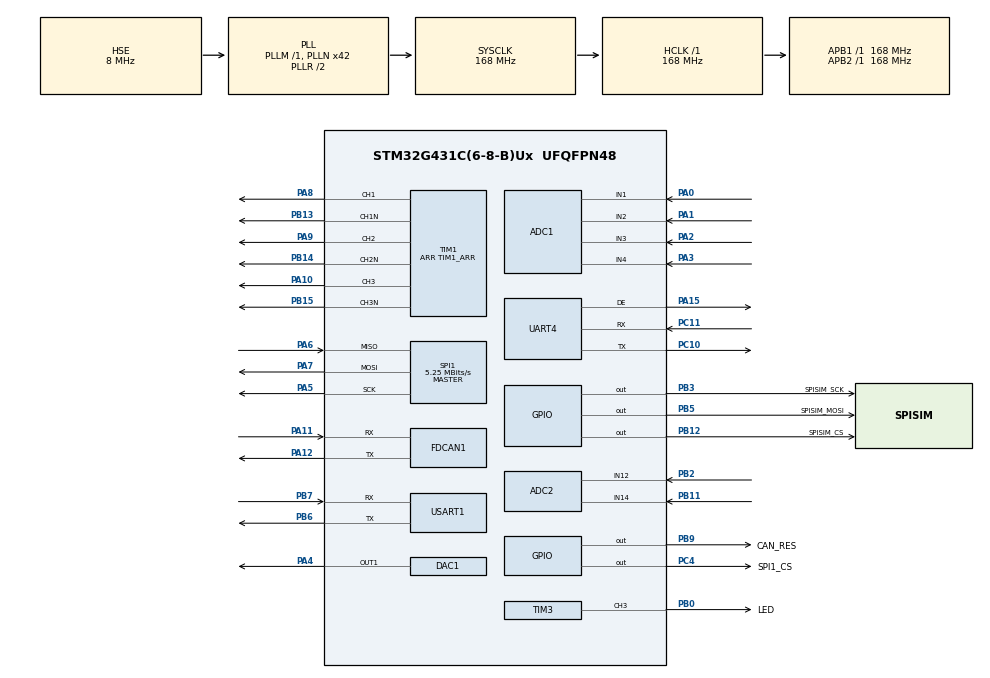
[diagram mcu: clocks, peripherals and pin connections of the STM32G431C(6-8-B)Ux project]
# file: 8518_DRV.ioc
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ADC1.Channel-10\#ChannelRegularConversion=ADC_CHANNEL_3
ADC1.Channel-5\#ChannelRegularConversion=ADC_CHANNEL_TEMPSENSOR_ADC1
ADC1.ContinuousConvMode=DISABLE
ADC1.DMAContinuousRequests=ENABLE
ADC1.EOCSelection=ADC_EOC_SEQ_CONV
ADC1.EnableInjectedConversion=ENABLE
ADC1.EnableInjectedOversampling=DISABLE
ADC1.EnableRegularConversion=ENABLE
ADC1.ExternalTrigConv=ADC_EXTERNALTRIG_T1_TRGO
ADC1.ExternalTrigConvEdge=ADC_EXTERNALTRIGCONVEDGE_RISING
ADC1.ExternalTrigInjecConv=ADC_EXTERNALTRIGINJEC_T1_CC4
ADC1.ExternalTrigInjecConvEdge=ADC_EXTERNALTRIGINJECCONV_EDGE_FALLING
ADC1.InjNumberOfConversion=3
ADC1.InjectedChannel-11\#ChannelInjectedConversion=ADC_CHANNEL_2
ADC1.InjectedChannel-12\#ChannelInjectedConversion=ADC_CHANNEL_4
ADC1.InjectedChannel-13\#ChannelInjectedConversion=ADC_CHANNEL_1
ADC1.InjectedConvMode=None
ADC1.InjectedOffsetNumber-11\#ChannelInjectedConversion=ADC_OFFSET_NONE
ADC1.InjectedOffsetNumber-12\#ChannelInjectedConversion=ADC_OFFSET_NONE
ADC1.InjectedOffsetNumber-13\#ChannelInjectedConversion=ADC_OFFSET_NONE
ADC1.InjectedRank-11\#ChannelInjectedConversion=1
ADC1.InjectedRank-12\#ChannelInjectedConversion=2
ADC1.InjectedRank-13\#ChannelInjectedConversion=3
ADC1.InjectedSamplingTime-11\#ChannelInjectedConversion=ADC_SAMPLETIME_2CYCLES_5
ADC1.InjectedSamplingTime-12\#ChannelInjectedConversion=ADC_SAMPLETIME_2CYCLES_5
ADC1.InjectedSamplingTime-13\#ChannelInjectedConversion=ADC_SAMPLETIME_2CYCLES_5
ADC1.NbrOfConversion=2
ADC1.NbrOfConversionFlag=1
ADC1.OffsetNumber-10\#ChannelRegularConversion=ADC_OFFSET_NONE
ADC1.OffsetNumber-5\#ChannelRegularConversion=ADC_OFFSET_NONE
ADC1.Overrun=ADC_OVR_DATA_OVERWRITTEN
ADC1.OversamplingMode=DISABLE
ADC1.Rank-10\#ChannelRegularConversion=2
ADC1.Rank-5\#ChannelRegularConversion=1
ADC1.Rank1_Channel=ADC_CHANNEL_2
ADC1.Rank2_Channel=ADC_CHANNEL_4
ADC1.Rank3_Channel=ADC_CHANNEL_1
ADC1.Rank4_Channel=ADC_CHANNEL_4
ADC1.SamplingTime-10\#ChannelRegularConversion=ADC_SAMPLETIME_2CYCLES_5
ADC1.SamplingTime-5\#ChannelRegularConversion=ADC_SAMPLETIME_2CYCLES_5
ADC1.injectedQueueMode=DISABLE
ADC1.master=1
ADC2.Channel-7\#ChannelRegularConversion=ADC_CHANNEL_12
ADC2.Channel-8\#ChannelRegularConversion=ADC_CHANNEL_14
ADC2.ContinuousConvMode=DISABLE
ADC2.DMAContinuousRequests=ENABLE
ADC2.EOCSelection=ADC_EOC_SEQ_CONV
ADC2.ExternalTrigConv=ADC_EXTERNALTRIG_T1_TRGO
ADC2.NbrOfConversion=2
ADC2.NbrOfConversionFlag=1
ADC2.OffsetNumber-7\#ChannelRegularConversion=ADC_OFFSET_NONE
ADC2.OffsetNumber-8\#ChannelRegularConversion=ADC_OFFSET_NONE
ADC2.Overrun=ADC_OVR_DATA_OVERWRITTEN
ADC2.Rank-7\#ChannelRegularConversion=1
ADC2.Rank-8\#ChannelRegularConversion=2
ADC2.SamplingTime-7\#ChannelRegularConversion=ADC_SAMPLETIME_2CYCLES_5
ADC2.SamplingTime-8\#ChannelRegularConversion=ADC_SAMPLETIME_2CYCLES_5
Dma.ADC1.0.Direction=DMA_PERIPH_TO_MEMORY
Dma.ADC1.0.EventEnable=DISABLE
Dma.ADC1.0.Instance=DMA1_Channel1
Dma.ADC1.0.MemDataAlignment=DMA_MDATAALIGN_HALFWORD
Dma.ADC1.0.MemInc=DMA_MINC_ENABLE
Dma.ADC1.0.Mode=DMA_CIRCULAR
Dma.ADC1.0.PeriphDataAlignment=DMA_PDATAALIGN_HALFWORD
Dma.ADC1.0.PeriphInc=DMA_PINC_DISABLE
Dma.ADC1.0.Polarity=HAL_DMAMUX_REQ_GEN_RISING
Dma.ADC1.0.Priority=DMA_PRIORITY_LOW
Dma.ADC1.0.RequestNumber=1
Dma.ADC1.0.SignalID=NONE
Dma.ADC1.0.SyncEnable=DISABLE
Dma.ADC1.0.SyncPolarity=HAL_DMAMUX_SYNC_NO_EVENT
Dma.ADC1.0.SyncRequestNumber=1
Dma.ADC1.0.SyncSignalID=NONE
Dma.ADC2.1.Direction=DMA_PERIPH_TO_MEMORY
Dma.ADC2.1.EventEnable=DISABLE
Dma.ADC2.1.Instance=DMA1_Channel2
Dma.ADC2.1.MemDataAlignment=DMA_MDATAALIGN_HALFWORD
Dma.ADC2.1.MemInc=DMA_MINC_ENABLE
Dma.ADC2.1.Mode=DMA_CIRCULAR
Dma.ADC2.1.PeriphDataAlignment=DMA_PDATAALIGN_HALFWORD
Dma.ADC2.1.PeriphInc=DMA_PINC_DISABLE
Dma.ADC2.1.Polarity=HAL_DMAMUX_REQ_GEN_RISING
Dma.ADC2.1.Priority=DMA_PRIORITY_LOW
Dma.ADC2.1.RequestNumber=1
Dma.ADC2.1.SignalID=NONE
Dma.ADC2.1.SyncEnable=DISABLE
Dma.ADC2.1.SyncPolarity=HAL_DMAMUX_SYNC_NO_EVENT
Dma.ADC2.1.SyncRequestNumber=1
Dma.ADC2.1.SyncSignalID=NONE
Dma.Request0=ADC1
Dma.Request1=ADC2
FDCAN1.AutoRetransmission=ENABLE
FDCAN1.CalculateBaudRateNominal=1000000
FDCAN1.CalculateTimeBitNominal=1000
FDCAN1.CalculateTimeQuantumNominal=125.0
FDCAN1.DataPrescaler=3
FDCAN1.DataSyncJumpWidth=10
FDCAN1.DataTimeSeg1=29
FDCAN1.DataTimeSeg2=10
FDCAN1.NominalPrescaler=1
FDCAN1.NominalSyncJumpWidth=10
FDCAN1.NominalTimeSeg1=5
FDCAN1.NominalTimeSeg2=2
FDCAN1.ProtocolException=ENABLE
FDCAN1.StdFiltersNbr=1
Mcu.Family=STM32G4
Mcu.Name=STM32G431C(6-8-B)Ux
Mcu.Package=UFQFPN48
Mcu.UserConstants=TIM6_ARR,1000-1;TIM3_ARR,1000-1;TIM1_ARR,3500;TIM7_ARR,200-1
NVIC.ADC1_2_IRQn=true\:0\:0\:false\:false\:true\:true\:true\:true
NVIC.DMA1_Channel1_IRQn=true\:0\:0\:false\:false\:true\:false\:true\:true
NVIC.DMA1_Channel2_IRQn=true\:0\:0\:false\:false\:true\:false\:true\:true
NVIC.FDCAN1_IT0_IRQn=true\:0\:0\:false\:false\:true\:true\:true\:true
NVIC.FDCAN1_IT1_IRQn=true\:0\:0\:false\:false\:true\:true\:true\:true
NVIC.PriorityGroup=NVIC_PRIORITYGROUP_4
NVIC.TIM3_IRQn=true\:4\:0\:true\:false\:true\:true\:true\:true
NVIC.TIM6_DAC_IRQn=true\:1\:0\:true\:false\:true\:true\:true\:true
NVIC.TIM7_IRQn=true\:0\:0\:true\:false\:true\:true\:true\:true
PA0.Mode=IN1-Single-Ended
PA0.Signal=ADC1_IN1
PA1.Mode=IN2-Single-Ended
PA1.Signal=ADC1_IN2
PA10.Signal=S_TIM1_CH3
PA11.Mode=FDCAN_Activate
PA11.Signal=FDCAN1_RX
PA12.Mode=FDCAN_Activate
PA12.Signal=FDCAN1_TX
PA13.Mode=Serial_Wire
PA13.Signal=SYS_JTMS-SWDIO
PA14.Mode=Serial_Wire
PA14.Signal=SYS_JTCK-SWCLK
PA15.Mode=Hardware Flow Control (RS485)
PA15.Signal=UART4_DE
PA2.Mode=IN3-Single-Ended
PA2.Signal=ADC1_IN3
PA3.Mode=IN4-Single-Ended
PA3.Signal=ADC1_IN4
PA4.Signal=COMP_DAC11_group
PA5.Mode=Full_Duplex_Master
PA5.Signal=SPI1_SCK
PA6.Mode=Full_Duplex_Master
PA6.Signal=SPI1_MISO
PA7.Mode=Full_Duplex_Master
PA7.Signal=SPI1_MOSI
PA8.Signal=S_TIM1_CH1
PA9.Signal=S_TIM1_CH2
PB0.GPIO_Label=LED
PB0.Signal=S_TIM3_CH3
PB11.Mode=IN14-Single-Ended
PB11.Signal=ADC2_IN14
PB12.GPIO_Label=SPISIM_CS
PB12.GPIO_ModeDefaultOutputPP=GPIO_MODE_OUTPUT_PP
PB12.GPIO_PuPd=GPIO_PULLUP
PB12.GPIO_Speed=GPIO_SPEED_FREQ_VERY_HIGH
PB12.PinState=GPIO_PIN_RESET
PB12.Signal=GPIO_Output
PB13.Mode=PWM Generation1 CH1 CH1N
PB13.Signal=TIM1_CH1N
PB14.Mode=PWM Generation2 CH2 CH2N
PB14.Signal=TIM1_CH2N
PB15.Mode=PWM Generation3 CH3 CH3N
PB15.Signal=TIM1_CH3N
PB2.Mode=IN12-Single-Ended
PB2.Signal=ADC2_IN12
PB3.GPIO_Label=SPISIM_SCK
PB3.GPIO_PuPd=GPIO_PULLDOWN
PB3.GPIO_Speed=GPIO_SPEED_FREQ_VERY_HIGH
PB3.Signal=GPIO_Output
PB5.GPIO_Label=SPISIM_MOSI
PB5.GPIO_PuPd=GPIO_NOPULL
PB5.GPIO_Speed=GPIO_SPEED_FREQ_VERY_HIGH
PB5.Signal=GPIO_Output
PB6.Mode=Asynchronous
PB6.Signal=USART1_TX
PB7.Mode=Asynchronous
PB7.Signal=USART1_RX
PB9.GPIO_Label=CAN_RES
PB9.Signal=GPIO_Output
PC10.Mode=Asynchronous
PC10.Signal=UART4_TX
PC11.Mode=Asynchronous
PC11.Signal=UART4_RX
PC4.GPIO_Label=SPI1_CS
PC4.GPIO_Speed=GPIO_SPEED_FREQ_VERY_HIGH
PC4.Signal=GPIO_Output
PF0-OSC_IN.Mode=HSE-External-Oscillator
PF0-OSC_IN.Signal=RCC_OSC_IN
PF1-OSC_OUT.Mode=HSE-External-Oscillator
PF1-OSC_OUT.Signal=RCC_OSC_OUT
ProjectManager.HeapSize=0x2000
ProjectManager.StackSize=0x4000
ProjectManager.TargetToolchain=CMake
RCC.ADC12Freq_Value=168000000
RCC.AHBFreq_Value=168000000
RCC.APB1Freq_Value=168000000
RCC.APB1TimFreq_Value=168000000
RCC.APB2Freq_Value=168000000
RCC.APB2TimFreq_Value=168000000
RCC.CortexFreq_Value=168000000
RCC.EXTERNAL_CLOCK_VALUE=12288000
RCC.FDCANCLockSelection=RCC_FDCANCLKSOURCE_HSE
RCC.HCLKFreq_Value=168000000
RCC.HSE_VALUE=8000000
RCC.HSI48_VALUE=48000000
RCC.HSI_VALUE=16000000
RCC.LSE_VALUE=32768
RCC.PLLN=42
RCC.PLLSourceVirtual=RCC_PLLSOURCE_HSE
RCC.SYSCLKFreq_VALUE=168000000
RCC.SYSCLKSource=RCC_SYSCLKSOURCE_PLLCLK
RCC.USBFreq_Value=168000000
RCC.VCOOutputFreq_Value=336000000
SH.COMP_DAC11_group.0=DAC1_OUT1,DAC_OUT1_ExtAndInt
SH.S_TIM1_CH1.0=TIM1_CH1,PWM Generation1 CH1 CH1N
SH.S_TIM1_CH2.0=TIM1_CH2,PWM Generation2 CH2 CH2N
SH.S_TIM1_CH3.0=TIM1_CH3,PWM Generation3 CH3 CH3N
SH.S_TIM3_CH3.0=TIM3_CH3,PWM Generation3 CH3
SPI1.BaudRatePrescaler=SPI_BAUDRATEPRESCALER_32
SPI1.CLKPhase=SPI_PHASE_2EDGE
SPI1.CLKPolarity=SPI_POLARITY_HIGH
SPI1.CalculateBaudRate=5.25 MBits/s
SPI1.DataSize=SPI_DATASIZE_8BIT
SPI1.Direction=SPI_DIRECTION_2LINES
SPI1.Mode=SPI_MODE_MASTER
SPI1.VirtualType=VM_MASTER
STMicroelectronics.X-CUBE-ALGOBUILD.1.4.0.LibraryCcDSPOoLibraryJjDSPOoLibrary=true
TIM1.AutoReloadPreload=TIM_AUTORELOAD_PRELOAD_ENABLE
TIM1.AutomaticOutput=TIM_AUTOMATICOUTPUT_ENABLE
TIM1.Channel-PWM\ Generation1\ CH1\ CH1N=TIM_CHANNEL_1
TIM1.Channel-PWM\ Generation2\ CH2\ CH2N=TIM_CHANNEL_2
TIM1.Channel-PWM\ Generation3\ CH3\ CH3N=TIM_CHANNEL_3
TIM1.Channel-PWM\ Generation4\ No\ Output=TIM_CHANNEL_4
TIM1.CounterMode=TIM_COUNTERMODE_CENTERALIGNED1
TIM1.DeadTime=10
TIM1.Dithering=Disable
TIM1.OCMode_PWM-PWM\ Generation1\ CH1\ CH1N=TIM_OCMODE_PWM1
TIM1.OCMode_PWM-PWM\ Generation2\ CH2\ CH2N=TIM_OCMODE_PWM1
TIM1.OCMode_PWM-PWM\ Generation3\ CH3\ CH3N=TIM_OCMODE_PWM1
TIM1.OCMode_PWM-PWM\ Generation4\ No\ Output=TIM_OCMODE_PWM1
TIM1.OCNPolarity_1=TIM_OCNPOLARITY_HIGH
TIM1.OCNPolarity_2=TIM_OCNPOLARITY_HIGH
TIM1.OCNPolarity_3=TIM_OCNPOLARITY_HIGH
TIM1.OCPolarity_1=TIM_OCPOLARITY_HIGH
TIM1.OCPolarity_2=TIM_OCPOLARITY_HIGH
TIM1.OCPolarity_3=TIM_OCPOLARITY_HIGH
TIM1.OCPolarity_4=TIM_OCPOLARITY_HIGH
TIM1.PeriodNoDither=TIM1_ARR
TIM1.TIM_MasterOutputTrigger=TIM_TRGO_OC4REF
TIM1.TIM_MasterOutputTrigger2=TIM_TRGO2_UPDATE
TIM1.TIM_MasterSlaveMode=TIM_MASTERSLAVEMODE_ENABLE
TIM17.AutoReloadPreload=TIM_AUTORELOAD_PRELOAD_DISABLE
TIM17.Dithering=Disable
TIM17.Fractionnal_PeriodDither=1
TIM17.Prescaler=170-1
TIM3.AutoReloadPreload=TIM_AUTORELOAD_PRELOAD_DISABLE
TIM3.Channel-PWM\ Generation3\ CH3=TIM_CHANNEL_3
TIM3.OCPolarity_3=TIM_OCPOLARITY_LOW
TIM3.PeriodNoDither=TIM3_ARR
TIM3.Prescaler=168-1
TIM6.AutoReloadPreload=TIM_AUTORELOAD_PRELOAD_ENABLE
TIM6.PeriodNoDither=TIM6_ARR
TIM6.Prescaler=168-1
TIM7.AutoReloadPreload=TIM_AUTORELOAD_PRELOAD_ENABLE
TIM7.PeriodNoDither=TIM7_ARR
TIM7.Prescaler=168-1
USART1.VirtualMode-Asynchronous=VM_ASYNC
VP_ADC1_TempSens_Input.Mode=IN-TempSens
VP_STMicroelectronics.X-CUBE-ALGOBUILD_VS_DSPOoLibraryJjLibrary_1.4.0_1.4.0.Mode=DSPOoLibraryJjLibrary
VP_SYS_VS_DBSignals.Mode=DisableDeadBatterySignals
VP_TIM17_VS_ClockSourceINT.Mode=Enable_Timer
VP_TIM1_VS_ClockSourceINT.Mode=Internal
VP_TIM1_VS_no_output4.Mode=PWM Generation4 No Output
VP_TIM3_VS_ClockSourceINT.Mode=Internal
VP_TIM6_VS_ClockSourceINT.Mode=Enable_Timer
VP_TIM7_VS_ClockSourceINT.Mode=Enable_Timer
board=custom

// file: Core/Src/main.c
/* USER CODE BEGIN Header */
/**
 ******************************************************************************
 * @file           : main.c
 * @brief          : Main program body
 ******************************************************************************
 * @attention
 *
 * Copyright (c) 2025 STMicroelectronics.
 * All rights reserved.
 *
 * This software is licensed under terms that can be found in the LICENSE file
 * in the root directory of this software component.
 * If no LICENSE file comes with this software, it is provided AS-IS.
 *
 ******************************************************************************
 */
/* USER CODE END Header */
#include "main.h"
#include "adc.h"
#include "dac.h"
#include "dma.h"
#include "fdcan.h"
#include "spi.h"
#include "tim.h"
#include "usart.h"
#include "gpio.h"

/* USER CODE BEGIN Includes */

#include "app_main.h"
/* USER CODE END Includes */

void SystemClock_Config(void);

int main(void)
{

  /* MCU Configuration--------------------------------------------------------*/

  /* Reset of all peripherals, Initializes the Flash interface and the Systick. */
  HAL_Init();

  /* Configure the system clock */
  SystemClock_Config();

  /* Initialize all configured peripherals */
  MX_GPIO_Init();
  MX_DMA_Init();
  MX_ADC1_Init();
  MX_ADC2_Init();
  MX_DAC1_Init();
  MX_FDCAN1_Init();
  MX_SPI1_Init();
  MX_TIM1_Init();
  MX_UART4_Init();
  MX_USART1_UART_Init();
  MX_TIM3_Init();
  MX_TIM6_Init();
  MX_TIM17_Init();
  MX_TIM7_Init();
  /* USER CODE BEGIN 2 */
  App_Main_Init();
  /* USER CODE END 2 */

  /* Infinite loop */
  /* USER CODE BEGIN WHILE */
  while (1) {
    App_Main_Loop();
    /* USER CODE END WHILE */

  }
}

void SystemClock_Config(void)
{
  RCC_OscInitTypeDef RCC_OscInitStruct = {0};
  RCC_ClkInitTypeDef RCC_ClkInitStruct = {0};

  /** Configure the main internal regulator output voltage
  */
  HAL_PWREx_ControlVoltageScaling(PWR_REGULATOR_VOLTAGE_SCALE1_BOOST);

  /** Initializes the RCC Oscillators according to the specified parameters
  * in the RCC_OscInitTypeDef structure.
  */
  RCC_OscInitStruct.OscillatorType = RCC_OSCILLATORTYPE_HSE;
  RCC_OscInitStruct.HSEState = RCC_HSE_ON;
  RCC_OscInitStruct.PLL.PLLState = RCC_PLL_ON;
  RCC_OscInitStruct.PLL.PLLSource = RCC_PLLSOURCE_HSE;
  RCC_OscInitStruct.PLL.PLLM = RCC_PLLM_DIV1;
  RCC_OscInitStruct.PLL.PLLN = 42;
  RCC_OscInitStruct.PLL.PLLP = RCC_PLLP_DIV2;
  RCC_OscInitStruct.PLL.PLLQ = RCC_PLLQ_DIV2;
  RCC_OscInitStruct.PLL.PLLR = RCC_PLLR_DIV2;
  if (HAL_RCC_OscConfig(&RCC_OscInitStruct) != HAL_OK)
  {
    Error_Handler();
  }

  /** Initializes the CPU, AHB and APB buses clocks
  */
  RCC_ClkInitStruct.ClockType = RCC_CLOCKTYPE_HCLK|RCC_CLOCKTYPE_SYSCLK
                              |RCC_CLOCKTYPE_PCLK1|RCC_CLOCKTYPE_PCLK2;
  RCC_ClkInitStruct.SYSCLKSource = RCC_SYSCLKSOURCE_PLLCLK;
  RCC_ClkInitStruct.AHBCLKDivider = RCC_SYSCLK_DIV1;
  RCC_ClkInitStruct.APB1CLKDivider = RCC_HCLK_DIV1;
  RCC_ClkInitStruct.APB2CLKDivider = RCC_HCLK_DIV1;

  if (HAL_RCC_ClockConfig(&RCC_ClkInitStruct, FLASH_LATENCY_4) != HAL_OK)
  {
    Error_Handler();
  }
}

void Error_Handler(void)
{
  __disable_irq();
  while (1) {
  }
}

#ifdef  USE_FULL_ASSERT
/**
  * @brief  Reports the name of the source file and the source line number
  *         where the assert_param error has occurred.
  * @param  file: pointer to the source file name
  * @param  line: assert_param error line source number
  * @retval None
  */
void assert_failed(uint8_t *file, uint32_t line)
{
  /* USER CODE BEGIN 6 */
  /* User can add his own implementation to report the file name and line
     number, ex: printf("Wrong parameters value: file %s on line %d\r\n", file,
     line) */
  /* USER CODE END 6 */
}
#endif /* USE_FULL_ASSERT */
